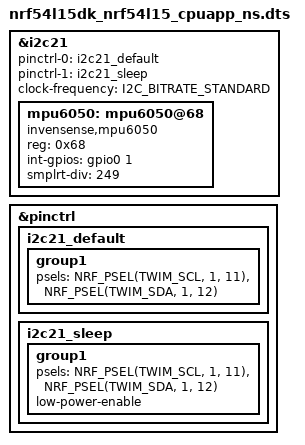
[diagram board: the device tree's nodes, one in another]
&i2c21 {
    status = "okay";
    pinctrl-0 = <&i2c21_default>;
    pinctrl-1 = <&i2c21_sleep>;
    pinctrl-names = "default", "sleep";
    mpu6050: mpu6050@68 {compatible = "invensense,mpu6050";
        reg = <0x68>; status = "okay";
        int-gpios = <&gpio0 1 GPIO_ACTIVE_HIGH>; smplrt-div = <249>;
    };
    clock-frequency = <I2C_BITRATE_STANDARD>;
};


&pinctrl {
    /omit-if-no-ref/ i2c21_default: i2c21_default {
        group1 { psels = <NRF_PSEL(TWIM_SCL, 1, 11)>, <NRF_PSEL(TWIM_SDA, 1, 12)>; };
    };
    /omit-if-no-ref/ i2c21_sleep: i2c21_sleep {
        group1 { psels = <NRF_PSEL(TWIM_SCL, 1, 11)>, <NRF_PSEL(TWIM_SDA, 1, 12)>; low-power-enable; };
    };
};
